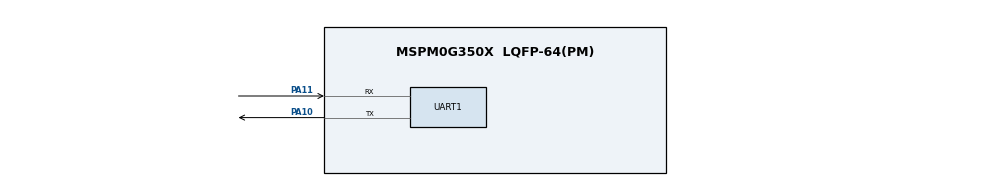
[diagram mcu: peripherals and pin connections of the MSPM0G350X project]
/**
 * @cliArgs --device "MSPM0G350X" --part "Default" --package "LQFP-64(PM)" --product "mspm0_sdk@2.05.01.01"
 * @versions {"tool":"1.24.0+4110"}
 */

/**
 * Import the modules used in this configuration.
 */
const Board         = scripting.addModule("/ti/driverlib/Board");
const GPIO          = scripting.addModule("/ti/driverlib/GPIO", {}, false);
const GPIO1         = GPIO.addInstance();
const SYSCTL        = scripting.addModule("/ti/driverlib/SYSCTL");
const UART          = scripting.addModule("/ti/driverlib/UART", {}, false);
const UART1         = UART.addInstance();
const ProjectConfig = scripting.addModule("/ti/project_config/ProjectConfig");

/**
 * Write custom configuration values to the imported modules.
 */
Board.peripheral.$assign = "DEBUGSS";

GPIO1.$name                          = "GPIO";
GPIO1.associatedPins[0].assignedPort = "PORTB";
GPIO1.associatedPins[0].$name        = "GREEN_LED";
GPIO1.associatedPins[0].assignedPin  = "27";

SYSCTL.forceDefaultClkConfig = true;

UART1.targetBaudRate                   = 115200;
UART1.$name                            = "CONSOLE_UART";
UART1.enabledInterrupts                = ["RX"];
UART1.peripheral.$assign               = "UART0";
UART1.peripheral.rxPin.$assign         = "PA11";
UART1.peripheral.txPin.$assign         = "PA10";
UART1.txPinConfig.$name                = "ti_driverlib_gpio_GPIOPinGeneric0";
UART1.txPinConfig.direction            = scripting.forceWrite("OUTPUT");
UART1.txPinConfig.hideOutputInversion  = scripting.forceWrite(false);
UART1.txPinConfig.onlyInternalResistor = scripting.forceWrite(false);
UART1.txPinConfig.passedPeripheralType = scripting.forceWrite("Digital");
UART1.rxPinConfig.$name                = "ti_driverlib_gpio_GPIOPinGeneric1";
UART1.rxPinConfig.hideOutputInversion  = scripting.forceWrite(false);
UART1.rxPinConfig.onlyInternalResistor = scripting.forceWrite(false);
UART1.rxPinConfig.passedPeripheralType = scripting.forceWrite("Digital");

ProjectConfig.genLinker = false;

/**
 * Pinmux solution for unlocked pins/peripherals. This ensures that minor changes to the automatic solver in a future
 * version of the tool will not impact the pinmux you originally saw.  These lines can be completely deleted in order to
 * re-solve from scratch.
 */
Board.peripheral.swclkPin.$suggestSolution   = "PA20";
Board.peripheral.swdioPin.$suggestSolution   = "PA19";
GPIO1.associatedPins[0].pin.$suggestSolution = "PB27";
SYSCTL.peripheral.$suggestSolution           = "SYSCTL";
